AUTOSAR XML (schema 4-3-0)
package /ComponentTypes
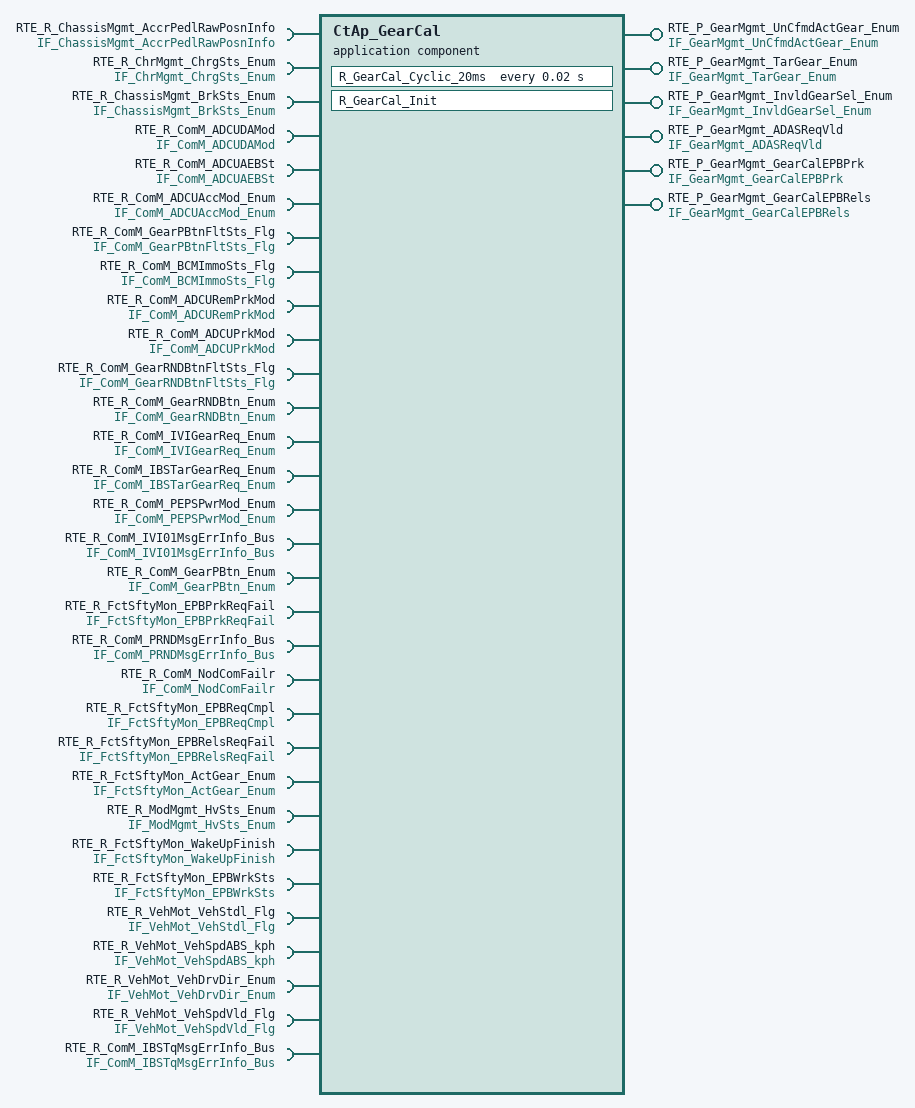
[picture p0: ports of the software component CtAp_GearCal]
  application sw component type CtAp_GearCal
    6 x provide port:
      RTE_P_GearMgmt_UnCfmdActGear_Enum: nonqueued-sender-com-spec{data-element=tec_GearMgmt_UnCfmdActGear_Enum, init-value=0}, provided-interface=IF_GearMgmt_UnCfmdActGear_Enum
      RTE_P_GearMgmt_TarGear_Enum: nonqueued-sender-com-spec{data-element=tec_GearMgmt_TarGear_Enum, init-value=0}, provided-interface=IF_GearMgmt_TarGear_Enum
      RTE_P_GearMgmt_InvldGearSel_Enum: nonqueued-sender-com-spec{data-element=tec_GearMgmt_InvldGearSel_Enum, init-value=0}, provided-interface=IF_GearMgmt_InvldGearSel_Enum
      RTE_P_GearMgmt_ADASReqVld: nonqueued-sender-com-spec{data-element=tec_GearMgmt_ADASReqVld, init-value=0}, provided-interface=IF_GearMgmt_ADASReqVld
      RTE_P_GearMgmt_GearCalEPBPrk: nonqueued-sender-com-spec{data-element=tec_GearMgmt_GearCalEPBPrk, init-value=0}, provided-interface=IF_GearMgmt_GearCalEPBPrk
      RTE_P_GearMgmt_GearCalEPBRels: nonqueued-sender-com-spec{data-element=tec_GearMgmt_GearCalEPBRels, init-value=0}, provided-interface=IF_GearMgmt_GearCalEPBRels
    31 x require port:
      RTE_R_ChassisMgmt_AccrPedlRawPosnInfo: nonqueued-receiver-com-spec{data-element=tec_ChassisMgmt_AccrPedlRawPosnInfo, filter=data-filter-type=ALWAYS, init-value=0}, required-interface=IF_ChassisMgmt_AccrPedlRawPosnInfo
      RTE_R_ChrMgmt_ChrgSts_Enum: nonqueued-receiver-com-spec{data-element=tec_ChrMgmt_ChrgSts_Enum, filter=data-filter-type=ALWAYS, init-value=0}, required-interface=IF_ChrMgmt_ChrgSts_Enum
      RTE_R_ChassisMgmt_BrkSts_Enum: nonqueued-receiver-com-spec{data-element=tec_ChassisMgmt_BrkSts_Enum, filter=data-filter-type=ALWAYS, init-value=0}, required-interface=IF_ChassisMgmt_BrkSts_Enum
      RTE_R_ComM_ADCUDAMod: nonqueued-receiver-com-spec{data-element=tec_ComM_ADCUDAMod, filter=data-filter-type=ALWAYS, init-value=0}, required-interface=IF_ComM_ADCUDAMod
      RTE_R_ComM_ADCUAEBSt: nonqueued-receiver-com-spec{data-element=tec_ComM_ADCUAEBSt, filter=data-filter-type=ALWAYS, init-value=0}, required-interface=IF_ComM_ADCUAEBSt
      RTE_R_ComM_ADCUAccMod_Enum: nonqueued-receiver-com-spec{data-element=tec_ComM_ADCUAccMod_Enum, filter=data-filter-type=ALWAYS, init-value=0}, required-interface=IF_ComM_ADCUAccMod_Enum
      RTE_R_ComM_GearPBtnFltSts_Flg: nonqueued-receiver-com-spec{data-element=tec_ComM_GearPBtnFltSts_Flg, filter=data-filter-type=ALWAYS, init-value=0}, required-interface=IF_ComM_GearPBtnFltSts_Flg
      RTE_R_ComM_BCMImmoSts_Flg: nonqueued-receiver-com-spec{data-element=tec_ComM_BCMImmoSts_Flg, filter=data-filter-type=ALWAYS, init-value=0}, required-interface=IF_ComM_BCMImmoSts_Flg
      RTE_R_ComM_ADCURemPrkMod: nonqueued-receiver-com-spec{data-element=tec_ComM_ADCURemPrkMod, filter=data-filter-type=ALWAYS, init-value=0}, required-interface=IF_ComM_ADCURemPrkMod
      RTE_R_ComM_ADCUPrkMod: nonqueued-receiver-com-spec{data-element=tec_ComM_ADCUPrkMod, filter=data-filter-type=ALWAYS, init-value=0}, required-interface=IF_ComM_ADCUPrkMod
      RTE_R_ComM_GearRNDBtnFltSts_Flg: nonqueued-receiver-com-spec{data-element=tec_ComM_GearRNDBtnFltSts_Flg, filter=data-filter-type=ALWAYS, init-value=0}, required-interface=IF_ComM_GearRNDBtnFltSts_Flg
      RTE_R_ComM_GearRNDBtn_Enum: nonqueued-receiver-com-spec{data-element=tec_ComM_GearRNDBtn_Enum, filter=data-filter-type=ALWAYS, init-value=0}, required-interface=IF_ComM_GearRNDBtn_Enum
      RTE_R_ComM_IVIGearReq_Enum: nonqueued-receiver-com-spec{data-element=tec_ComM_IVIGearReq_Enum, filter=data-filter-type=ALWAYS, init-value=0}, required-interface=IF_ComM_IVIGearReq_Enum
      RTE_R_ComM_IBSTarGearReq_Enum: nonqueued-receiver-com-spec{data-element=tec_ComM_IBSTarGearReq_Enum, filter=data-filter-type=ALWAYS, init-value=0}, required-interface=IF_ComM_IBSTarGearReq_Enum
      RTE_R_ComM_PEPSPwrMod_Enum: nonqueued-receiver-com-spec{data-element=tec_ComM_PEPSPwrMod_Enum, filter=data-filter-type=ALWAYS, init-value=0}, required-interface=IF_ComM_PEPSPwrMod_Enum
      RTE_R_ComM_IVI01MsgErrInfo_Bus: required-interface=IF_ComM_IVI01MsgErrInfo_Bus
        required-com-specs:
          data-element=tec_ComM_IVI01CRCInfo_Bus, filter=data-filter-type=ALWAYS, init-value=fields=[ComM_MonStatIVI01CRCErrorInfo:0, ComM_MonResIVI01CRCErrorInfo:0, ComM_ErrStatIVI01CRCErrorInfo:0, ComM_ErrResIVI01CRCErrorInfo:0]
          data-element=tec_ComM_IVI01E2ETimeoutInfo_Bus, filter=data-filter-type=ALWAYS, init-value=fields=[ComM_MonStatIVI01E2ETimeoutInfo:0, ComM_MonResIVI01E2ETimeoutInfo:0, ComM_ErrStatIVI01E2ETimeoutInfo:0, ComM_ErrResIVI01E2ETimeoutInfo:0]
      RTE_R_ComM_GearPBtn_Enum: nonqueued-receiver-com-spec{data-element=tec_ComM_GearPBtn_Enum, filter=data-filter-type=ALWAYS, init-value=0}, required-interface=IF_ComM_GearPBtn_Enum
      RTE_R_FctSftyMon_EPBPrkReqFail: nonqueued-receiver-com-spec{data-element=tec_FctSftyMon_EPBPrkReqFail, filter=data-filter-type=ALWAYS, init-value=0}, required-interface=IF_FctSftyMon_EPBPrkReqFail
      RTE_R_ComM_PRNDMsgErrInfo_Bus: required-interface=IF_ComM_PRNDMsgErrInfo_Bus
        required-com-specs:
          data-element=tec_ComM_PRNDTimeoutInfo_Bus, filter=data-filter-type=ALWAYS, init-value=fields=[ComM_MonStatPRNDTimeoutInfo:0, ComM_MonResPRNDTimeoutInfo:0, ComM_ErrStatPRNDTimeoutInfo:0, ComM_ErrResPRNDTimeoutInfo:0]
          data-element=tec_ComM_PRNDCRCDTCInfo_Bus, filter=data-filter-type=ALWAYS, init-value=fields=[ComM_MonStatPRNDCRCDTCErrorInfo:0, ComM_MonResPRNDCRCDTCErrorInfo:0, ComM_ErrStatPRNDCRCDTCErrorInfo:0, ComM_ErrResPRNDCRCDTCErrorInfo:0]
          data-element=tec_ComM_PRNDCRCInfo_Bus, filter=data-filter-type=ALWAYS, init-value=fields=[ComM_MonStatPRNDCRCErrorInfo:0, ComM_MonResPRNDCRCErrorInfo:0, ComM_ErrStatPRNDCRCErrorInfo:0, ComM_ErrResPRNDCRCErrorInfo:0]
          data-element=tec_ComM_PRNDTimeoutDTCInfo_Bus, filter=data-filter-type=ALWAYS, init-value=fields=[ComM_MonStatPRNDTimeoutDTCErrorInfo:0, ComM_MonResPRNDTimeoutDTCErrorInfo:0, ComM_ErrStatPRNDTimeoutDTCErrorInfo:0, ComM_ErrResPRNDTimeoutDTCErrorInfo:0]
          data-element=tec_ComM_PRNDE2ETimeoutInfo_Bus, filter=data-filter-type=ALWAYS, init-value=fields=[ComM_MonStatPRNDE2ETimeoutInfo:0, ComM_MonResPRNDE2ETimeoutInfo:0, ComM_ErrStatPRNDE2ETimeoutInfo:0, ComM_ErrResPRNDE2ETimeoutInfo:0]
      RTE_R_ComM_NodComFailr: required-interface=IF_ComM_NodComFailr
        required-com-specs:
          data-element=tec_ComM_DCMRRNodComFailr_Flg, filter=data-filter-type=ALWAYS, init-value=0
          data-element=tec_ComM_DCMRLNodComFailr_Flg, filter=data-filter-type=ALWAYS, init-value=0
          data-element=tec_ComM_DCMFRNodComFailr_Flg, filter=data-filter-type=ALWAYS, init-value=0
          data-element=tec_ComM_DCMFLNodComFailr_Flg, filter=data-filter-type=ALWAYS, init-value=0
          data-element=tec_ComM_APTCNodComFailr_Flg, filter=data-filter-type=ALWAYS, init-value=0
          data-element=tec_ComM_ADCUNodComFailr_Flg, filter=data-filter-type=ALWAYS, init-value=0
          data-element=tec_ComM_ACUNodComFailr_Flg, filter=data-filter-type=ALWAYS, init-value=0
          data-element=tec_ComM_SGWNodComFailr_Flg, filter=data-filter-type=ALWAYS, init-value=0
          data-element=tec_ComM_CGWNodComFailr_Flg, filter=data-filter-type=ALWAYS, init-value=0
          data-element=tec_ComM_TCUNodComFailr_Flg, filter=data-filter-type=ALWAYS, init-value=0
          data-element=tec_ComM_BCMNodComFailr_Flg, filter=data-filter-type=ALWAYS, init-value=0
          data-element=tec_ComM_PRNDNodComFailr_Flg, filter=data-filter-type=ALWAYS, init-value=0
          data-element=tec_ComM_IVINodComFailr_Flg, filter=data-filter-type=ALWAYS, init-value=0
          data-element=tec_ComM_DCDCNodComFailr_Flg, filter=data-filter-type=ALWAYS, init-value=0
          data-element=tec_ComM_OBCNodComFailr_Flg, filter=data-filter-type=ALWAYS, init-value=0
          data-element=tec_ComM_CHIBSNodComFailr_Flg, filter=data-filter-type=ALWAYS, init-value=0
          data-element=tec_ComM_MCUNodComFailr_Flg, filter=data-filter-type=ALWAYS, init-value=0
          data-element=tec_ComM_EVCOMNodComFailr_Flg, filter=data-filter-type=ALWAYS, init-value=0
          data-element=tec_ComM_EPTIBSNodComFailr_Flg, filter=data-filter-type=ALWAYS, init-value=0
          data-element=tec_ComM_DCMNodComFailr_Flg, filter=data-filter-type=ALWAYS, init-value=0
          data-element=tec_ComM_BMSNodComFailr_Flg, filter=data-filter-type=ALWAYS, init-value=0
          data-element=tec_ComM_SGWCHNodComFailr_Flg, init-value=0
      RTE_R_FctSftyMon_EPBReqCmpl: nonqueued-receiver-com-spec{data-element=tec_FctSftyMon_EPBReqCmpl, filter=data-filter-type=ALWAYS, init-value=0}, required-interface=IF_FctSftyMon_EPBReqCmpl
      RTE_R_FctSftyMon_EPBRelsReqFail: nonqueued-receiver-com-spec{data-element=tec_FctSftyMon_EPBRelsReqFail, filter=data-filter-type=ALWAYS, init-value=0}, required-interface=IF_FctSftyMon_EPBRelsReqFail
      RTE_R_FctSftyMon_ActGear_Enum: nonqueued-receiver-com-spec{data-element=tec_FctSftyMon_ActGear_Enum, filter=data-filter-type=ALWAYS, init-value=0}, required-interface=IF_FctSftyMon_ActGear_Enum
      RTE_R_ModMgmt_HvSts_Enum: nonqueued-receiver-com-spec{data-element=tec_ModMgmt_HvSts_Enum, filter=data-filter-type=ALWAYS, init-value=0}, required-interface=IF_ModMgmt_HvSts_Enum
      RTE_R_FctSftyMon_WakeUpFinish: nonqueued-receiver-com-spec{data-element=tec_FctSftyMon_WakeUpFinish, filter=data-filter-type=ALWAYS, init-value=0}, required-interface=IF_FctSftyMon_WakeUpFinish
      RTE_R_FctSftyMon_EPBWrkSts: nonqueued-receiver-com-spec{data-element=tec_FctSftyMon_EPBWrkSts, filter=data-filter-type=ALWAYS, init-value=0}, required-interface=IF_FctSftyMon_EPBWrkSts
      RTE_R_VehMot_VehStdl_Flg: nonqueued-receiver-com-spec{data-element=tec_VehMot_VehStdl_Flg, filter=data-filter-type=ALWAYS, init-value=0}, required-interface=IF_VehMot_VehStdl_Flg
      RTE_R_VehMot_VehSpdABS_kph: nonqueued-receiver-com-spec{data-element=tec_VehMot_VehSpdABS_kph, filter=data-filter-type=ALWAYS, init-value=0}, required-interface=IF_VehMot_VehSpdABS_kph
      RTE_R_VehMot_VehDrvDir_Enum: nonqueued-receiver-com-spec{data-element=tec_VehMot_VehDrvDir_Enum, filter=data-filter-type=ALWAYS, init-value=0}, required-interface=IF_VehMot_VehDrvDir_Enum
      RTE_R_VehMot_VehSpdVld_Flg: nonqueued-receiver-com-spec{data-element=tec_VehMot_VehSpdVld_Flg, filter=data-filter-type=ALWAYS, init-value=0}, required-interface=IF_VehMot_VehSpdVld_Flg
      RTE_R_ComM_IBSTqMsgErrInfo_Bus: required-interface=IF_ComM_IBSTqMsgErrInfo_Bus
        required-com-specs:
          data-element=tec_ComM_IBSTqCRCDTCInfo_Bus, filter=data-filter-type=ALWAYS, init-value=fields=[ComM_MonStatIBSTqCRCDTCErrorInfo:0, ComM_MonResIBSTqCRCDTCErrorInfo:0, ComM_ErrStatIBSTqCRCDTCErrorInfo:0, ComM_ErrResIBSTqCRCDTCErrorInfo:0]
          data-element=tec_ComM_IBSTqTimeoutDTCInfo_Bus, filter=data-filter-type=ALWAYS, init-value=fields=[ComM_MonStatIBSTqTimeoutDTCErrorInfo:0, ComM_MonResIBSTqTimeoutDTCErrorInfo:0, ComM_ErrStatIBSTqTimeoutDTCErrorInfo:0, ComM_ErrResIBSTqTimeoutDTCErrorInfo:0]
          data-element=tec_ComM_IBSTqCRCInfo_Bus, filter=data-filter-type=ALWAYS, init-value=fields=[ComM_MonStatIBSTqCRCErrorInfo:0, ComM_MonResIBSTqCRCErrorInfo:0, ComM_ErrStatIBSTqCRCErrorInfo:0, ComM_ErrResIBSTqCRCErrorInfo:0]
          data-element=tec_ComM_IBSTqE2ETimeoutInfo_Bus, filter=data-filter-type=ALWAYS, init-value=fields=[ComM_MonStatIBSTqE2ETimeoutInfo:0, ComM_MonResIBSTqE2ETimeoutInfo:0, ComM_ErrStatIBSTqE2ETimeoutInfo:0, ComM_ErrResIBSTqE2ETimeoutInfo:0]
    behavior CtAp_GearCal_InternalBehavior
      timing event TMT_R_GearCal_Cyclic_20ms: start-on-event=R_GearCal_Cyclic_20ms, period=0.02
      init event CtAp_GearCal_InitEvent: start-on-event=R_GearCal_Init
      runnable R_GearCal_Cyclic_20ms
        data-receive-point-by-arguments:
          37 x access:
            REC_RTE_R_ChassisMgmt_AccrPedlRawPosnInfo_tec_ChassisMgmt_AccrPedlRawPosnInfo: accessed-variable=RTE_R_ChassisMgmt_AccrPedlRawPosnInfo.tec_ChassisMgmt_AccrPedlRawPosnInfo
            REC_RTE_R_ChassisMgmt_BrkSts_Enum_tec_ChassisMgmt_BrkSts_Enum: accessed-variable=RTE_R_ChassisMgmt_BrkSts_Enum.tec_ChassisMgmt_BrkSts_Enum
            REC_RTE_R_ChrMgmt_ChrgSts_Enum_tec_ChrMgmt_ChrgSts_Enum: accessed-variable=RTE_R_ChrMgmt_ChrgSts_Enum.tec_ChrMgmt_ChrgSts_Enum
            REC_RTE_R_ComM_ADCUAEBSt_tec_ComM_ADCUAEBSt: accessed-variable=RTE_R_ComM_ADCUAEBSt.tec_ComM_ADCUAEBSt
            REC_RTE_R_ComM_ADCUAccMod_Enum_tec_ComM_ADCUAccMod_Enum: accessed-variable=RTE_R_ComM_ADCUAccMod_Enum.tec_ComM_ADCUAccMod_Enum
            REC_RTE_R_ComM_ADCUDAMod_tec_ComM_ADCUDAMod: accessed-variable=RTE_R_ComM_ADCUDAMod.tec_ComM_ADCUDAMod
            REC_RTE_R_ComM_ADCUPrkMod_tec_ComM_ADCUPrkMod: accessed-variable=RTE_R_ComM_ADCUPrkMod.tec_ComM_ADCUPrkMod
            REC_RTE_R_ComM_ADCURemPrkMod_tec_ComM_ADCURemPrkMod: accessed-variable=RTE_R_ComM_ADCURemPrkMod.tec_ComM_ADCURemPrkMod
            REC_RTE_R_ComM_BCMImmoSts_Flg_tec_ComM_BCMImmoSts_Flg: accessed-variable=RTE_R_ComM_BCMImmoSts_Flg.tec_ComM_BCMImmoSts_Flg
            REC_RTE_R_ComM_GearPBtnFltSts_Flg_tec_ComM_GearPBtnFltSts_Flg: accessed-variable=RTE_R_ComM_GearPBtnFltSts_Flg.tec_ComM_GearPBtnFltSts_Flg
            REC_RTE_R_ComM_GearPBtn_Enum_tec_ComM_GearPBtn_Enum: accessed-variable=RTE_R_ComM_GearPBtn_Enum.tec_ComM_GearPBtn_Enum
            REC_RTE_R_ComM_GearRNDBtnFltSts_Flg_tec_ComM_GearRNDBtnFltSts_Flg: accessed-variable=RTE_R_ComM_GearRNDBtnFltSts_Flg.tec_ComM_GearRNDBtnFltSts_Flg
            REC_RTE_R_ComM_GearRNDBtn_Enum_tec_ComM_GearRNDBtn_Enum: accessed-variable=RTE_R_ComM_GearRNDBtn_Enum.tec_ComM_GearRNDBtn_Enum
            REC_RTE_R_ComM_IBSTarGearReq_Enum_tec_ComM_IBSTarGearReq_Enum: accessed-variable=RTE_R_ComM_IBSTarGearReq_Enum.tec_ComM_IBSTarGearReq_Enum
            REC_RTE_R_ComM_IVI01MsgErrInfo_Bus_tec_ComM_IVI01CRCInfo_Bus: accessed-variable=RTE_R_ComM_IVI01MsgErrInfo_Bus.tec_ComM_IVI01CRCInfo_Bus
            REC_RTE_R_ComM_IVI01MsgErrInfo_Bus_tec_ComM_IVI01E2ETimeoutInfo_Bus: accessed-variable=RTE_R_ComM_IVI01MsgErrInfo_Bus.tec_ComM_IVI01E2ETimeoutInfo_Bus
            REC_RTE_R_ComM_IVIGearReq_Enum_tec_ComM_IVIGearReq_Enum: accessed-variable=RTE_R_ComM_IVIGearReq_Enum.tec_ComM_IVIGearReq_Enum
            REC_RTE_R_ComM_NodComFailr_tec_ComM_ADCUNodComFailr_Flg: accessed-variable=RTE_R_ComM_NodComFailr.tec_ComM_ADCUNodComFailr_Flg
            REC_RTE_R_ComM_NodComFailr_tec_ComM_BCMNodComFailr_Flg: accessed-variable=RTE_R_ComM_NodComFailr.tec_ComM_BCMNodComFailr_Flg
            REC_RTE_R_ComM_NodComFailr_tec_ComM_CHIBSNodComFailr_Flg: accessed-variable=RTE_R_ComM_NodComFailr.tec_ComM_CHIBSNodComFailr_Flg
            REC_RTE_R_ComM_NodComFailr_tec_ComM_IVINodComFailr_Flg: accessed-variable=RTE_R_ComM_NodComFailr.tec_ComM_IVINodComFailr_Flg
            REC_RTE_R_ComM_NodComFailr_tec_ComM_PRNDNodComFailr_Flg: accessed-variable=RTE_R_ComM_NodComFailr.tec_ComM_PRNDNodComFailr_Flg
            REC_RTE_R_ComM_PEPSPwrMod_Enum_tec_ComM_PEPSPwrMod_Enum: accessed-variable=RTE_R_ComM_PEPSPwrMod_Enum.tec_ComM_PEPSPwrMod_Enum
            REC_RTE_R_ComM_PRNDMsgErrInfo_Bus_tec_ComM_PRNDCRCInfo_Bus: accessed-variable=RTE_R_ComM_PRNDMsgErrInfo_Bus.tec_ComM_PRNDCRCInfo_Bus
            REC_RTE_R_ComM_PRNDMsgErrInfo_Bus_tec_ComM_PRNDE2ETimeoutInfo_Bus: accessed-variable=RTE_R_ComM_PRNDMsgErrInfo_Bus.tec_ComM_PRNDE2ETimeoutInfo_Bus
            REC_RTE_R_FctSftyMon_ActGear_Enum_tec_FctSftyMon_ActGear_Enum: accessed-variable=RTE_R_FctSftyMon_ActGear_Enum.tec_FctSftyMon_ActGear_Enum
            REC_RTE_R_FctSftyMon_EPBPrkReqFail_tec_FctSftyMon_EPBPrkReqFail: accessed-variable=RTE_R_FctSftyMon_EPBPrkReqFail.tec_FctSftyMon_EPBPrkReqFail
            REC_RTE_R_FctSftyMon_EPBRelsReqFail_tec_FctSftyMon_EPBRelsReqFail: accessed-variable=RTE_R_FctSftyMon_EPBRelsReqFail.tec_FctSftyMon_EPBRelsReqFail
            REC_RTE_R_FctSftyMon_EPBReqCmpl_tec_FctSftyMon_EPBReqCmpl: accessed-variable=RTE_R_FctSftyMon_EPBReqCmpl.tec_FctSftyMon_EPBReqCmpl
            REC_RTE_R_FctSftyMon_EPBWrkSts_tec_FctSftyMon_EPBWrkSts: accessed-variable=RTE_R_FctSftyMon_EPBWrkSts.tec_FctSftyMon_EPBWrkSts
            REC_RTE_R_FctSftyMon_WakeUpFinish_tec_FctSftyMon_WakeUpFinish: accessed-variable=RTE_R_FctSftyMon_WakeUpFinish.tec_FctSftyMon_WakeUpFinish
            REC_RTE_R_ModMgmt_HvSts_Enum_tec_ModMgmt_HvSts_Enum: accessed-variable=RTE_R_ModMgmt_HvSts_Enum.tec_ModMgmt_HvSts_Enum
            REC_RTE_R_VehMot_VehDrvDir_Enum_tec_VehMot_VehDrvDir_Enum: accessed-variable=RTE_R_VehMot_VehDrvDir_Enum.tec_VehMot_VehDrvDir_Enum
            REC_RTE_R_VehMot_VehSpdABS_kph_tec_VehMot_VehSpdABS_kph: accessed-variable=RTE_R_VehMot_VehSpdABS_kph.tec_VehMot_VehSpdABS_kph
            REC_RTE_R_VehMot_VehSpdVld_Flg_tec_VehMot_VehSpdVld_Flg: accessed-variable=RTE_R_VehMot_VehSpdVld_Flg.tec_VehMot_VehSpdVld_Flg
            REC_RTE_R_VehMot_VehStdl_Flg_tec_VehMot_VehStdl_Flg: accessed-variable=RTE_R_VehMot_VehStdl_Flg.tec_VehMot_VehStdl_Flg
            REC_RTE_R_ComM_IBSTqMsgErrInfo_Bus_tec_ComM_IBSTqE2ETimeoutInfo_Bus: accessed-variable=RTE_R_ComM_IBSTqMsgErrInfo_Bus.tec_ComM_IBSTqE2ETimeoutInfo_Bus
        data-send-points:
          6 x access:
            SEND_RTE_P_GearMgmt_ADASReqVld_tec_GearMgmt_ADASReqVld: accessed-variable=RTE_P_GearMgmt_ADASReqVld.tec_GearMgmt_ADASReqVld
            SEND_RTE_P_GearMgmt_GearCalEPBPrk_tec_GearMgmt_GearCalEPBPrk: accessed-variable=RTE_P_GearMgmt_GearCalEPBPrk.tec_GearMgmt_GearCalEPBPrk
            SEND_RTE_P_GearMgmt_GearCalEPBRels_tec_GearMgmt_GearCalEPBRels: accessed-variable=RTE_P_GearMgmt_GearCalEPBRels.tec_GearMgmt_GearCalEPBRels
            SEND_RTE_P_GearMgmt_InvldGearSel_Enum_tec_GearMgmt_InvldGearSel_Enum: accessed-variable=RTE_P_GearMgmt_InvldGearSel_Enum.tec_GearMgmt_InvldGearSel_Enum
            SEND_RTE_P_GearMgmt_TarGear_Enum_tec_GearMgmt_TarGear_Enum: accessed-variable=RTE_P_GearMgmt_TarGear_Enum.tec_GearMgmt_TarGear_Enum
            SEND_RTE_P_GearMgmt_UnCfmdActGear_Enum_tec_GearMgmt_UnCfmdActGear_Enum: accessed-variable=RTE_P_GearMgmt_UnCfmdActGear_Enum.tec_GearMgmt_UnCfmdActGear_Enum
      runnable R_GearCal_Init
  swc implementation CtAp_GearCal_Implementation: behavior=CtAp_GearCal_InternalBehavior
